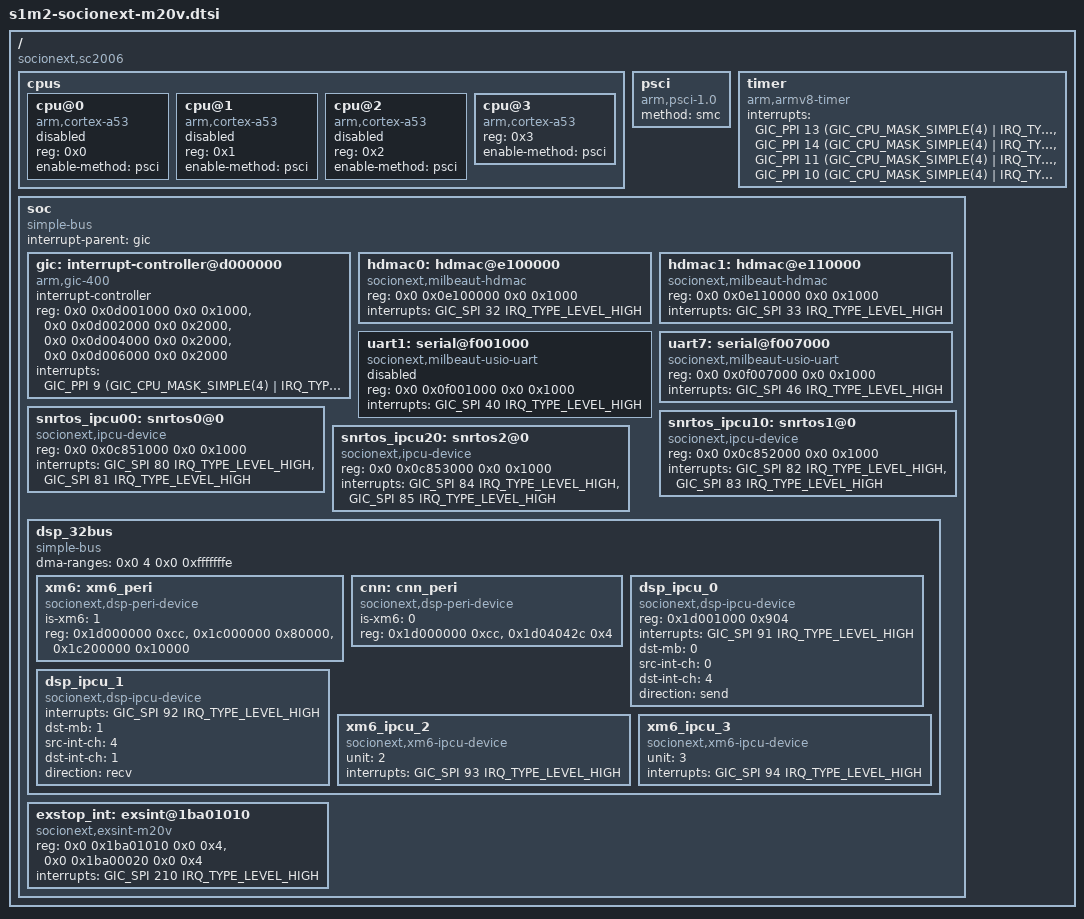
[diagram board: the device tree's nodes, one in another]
// SPDX-License-Identifier: GPL-2.0
/*
 * Reconstructed Device Tree Source for Socionext Milbeaut M20V (Karine / SC2006A)
 * Target: Panasonic LUMIX S1M2 (DC-S1M2)
 *
 * Platform: ARM64 Quad-Core Cortex-A53
 * AMP Architecture: Cores 0-2 (TOPPERS/ITRON RTOS), Core 3 (Linux 4.19)
 */

#include <dt-bindings/interrupt-controller/arm-gic.h>

/ {
	compatible = "socionext,sc2006", "socionext,m20v";
	#address-cells = <2>;
	#size-cells = <2>;

	cpus {
		#address-cells = <1>;
		#size-cells = <0>;

		cpu@0 {
			device_type = "cpu";
			compatible = "arm,cortex-a53", "arm,armv8";
			reg = <0x0>;
			enable-method = "psci";
			status = "disabled"; /* Reserved for RTOS Core 0: Shutter / ISP / Sensor / AF */
		};

		cpu@1 {
			device_type = "cpu";
			compatible = "arm,cortex-a53", "arm,armv8";
			reg = <0x1>;
			enable-method = "psci";
			status = "disabled"; /* Reserved for RTOS Core 1: DSP / CNN / Video Engine */
		};

		cpu@2 {
			device_type = "cpu";
			compatible = "arm,cortex-a53", "arm,armv8";
			reg = <0x2>;
			enable-method = "psci";
			status = "disabled"; /* Reserved for RTOS Core 2: Storage SD / Filesystem */
		};

		cpu@3 {
			device_type = "cpu";
			compatible = "arm,cortex-a53", "arm,armv8";
			reg = <0x3>;
			enable-method = "psci";
			status = "okay";     /* Linux 4.19 System Host: Wi-Fi, USB, OSD, Network */
		};
	};

	psci {
		compatible = "arm,psci-1.0", "arm,psci-0.2";
		method = "smc";
	};

	timer {
		compatible = "arm,armv8-timer";
		interrupts = <GIC_PPI 13 (GIC_CPU_MASK_SIMPLE(4) | IRQ_TYPE_LEVEL_LOW)>,
			     <GIC_PPI 14 (GIC_CPU_MASK_SIMPLE(4) | IRQ_TYPE_LEVEL_LOW)>,
			     <GIC_PPI 11 (GIC_CPU_MASK_SIMPLE(4) | IRQ_TYPE_LEVEL_LOW)>,
			     <GIC_PPI 10 (GIC_CPU_MASK_SIMPLE(4) | IRQ_TYPE_LEVEL_LOW)>;
	};

	soc {
		compatible = "simple-bus";
		#address-cells = <2>;
		#size-cells = <2>;
		ranges;
		interrupt-parent = <&gic>;

		gic: interrupt-controller@d000000 {
			compatible = "arm,gic-400";
			#interrupt-cells = <3>;
			interrupt-controller;
			reg = <0x0 0x0d001000 0x0 0x1000>,
			      <0x0 0x0d002000 0x0 0x2000>,
			      <0x0 0x0d004000 0x0 0x2000>,
			      <0x0 0x0d006000 0x0 0x2000>;
			interrupts = <GIC_PPI 9 (GIC_CPU_MASK_SIMPLE(4) | IRQ_TYPE_LEVEL_HIGH)>;
		};

		/* Hardware DMA Controllers */
		hdmac0: hdmac@e100000 {
			compatible = "socionext,milbeaut-hdmac";
			reg = <0x0 0x0e100000 0x0 0x1000>;
			interrupts = <GIC_SPI 32 IRQ_TYPE_LEVEL_HIGH>;
			#dma-cells = <1>;
		};

		hdmac1: hdmac@e110000 {
			compatible = "socionext,milbeaut-hdmac";
			reg = <0x0 0x0e110000 0x0 0x1000>;
			interrupts = <GIC_SPI 33 IRQ_TYPE_LEVEL_HIGH>;
			#dma-cells = <1>;
		};

		/* UART Controllers */
		uart1: serial@f001000 {
			compatible = "socionext,milbeaut-usio-uart";
			reg = <0x0 0x0f001000 0x0 0x1000>;
			interrupts = <GIC_SPI 40 IRQ_TYPE_LEVEL_HIGH>;
			status = "disabled";
		};

		uart7: serial@f007000 {
			compatible = "socionext,milbeaut-usio-uart";
			reg = <0x0 0x0f007000 0x0 0x1000>;
			interrupts = <GIC_SPI 46 IRQ_TYPE_LEVEL_HIGH>;
			status = "okay";
		};

		/* Inter-Processor Communication Unit (IPCU) Controllers */
		snrtos_ipcu00: snrtos0@0 {
			compatible = "socionext,ipcu-device";
			reg = <0x0 0x0c851000 0x0 0x1000>;
			interrupts = <GIC_SPI 80 IRQ_TYPE_LEVEL_HIGH>,
				     <GIC_SPI 81 IRQ_TYPE_LEVEL_HIGH>;
			status = "okay";
		};

		snrtos_ipcu10: snrtos1@0 {
			compatible = "socionext,ipcu-device";
			reg = <0x0 0x0c852000 0x0 0x1000>;
			interrupts = <GIC_SPI 82 IRQ_TYPE_LEVEL_HIGH>,
				     <GIC_SPI 83 IRQ_TYPE_LEVEL_HIGH>;
			status = "okay";
		};

		snrtos_ipcu20: snrtos2@0 {
			compatible = "socionext,ipcu-device";
			reg = <0x0 0x0c853000 0x0 0x1000>;
			interrupts = <GIC_SPI 84 IRQ_TYPE_LEVEL_HIGH>,
				     <GIC_SPI 85 IRQ_TYPE_LEVEL_HIGH>;
			status = "okay";
		};

		/* Dedicated 32-bit Peripheral Bus for XM6 DSP & CNN */
		dsp_32bus {
			compatible = "simple-bus";
			#address-cells = <1>;
			#size-cells = <1>;
			ranges = <0x0 0x0 0x0 0xfffffffe>;
			dma-ranges = <0x0 4 0x0 0xfffffffe>;

			/* CEVA XM6 Dual-Core Vector DSP */
			xm6: xm6_peri {
				compatible = "socionext,dsp-peri-device";
				is-xm6 = <1>;
				reg = <0x1d000000 0xcc>,       /* Control registers */
				      <0x1c000000 0x80000>,    /* 512 KiB DTCM */
				      <0x1c200000 0x10000>;    /* 64 KiB ITCM */
				status = "okay";
			};

			/* CNN Deep Learning Accelerator */
			cnn: cnn_peri {
				compatible = "socionext,dsp-peri-device";
				is-xm6 = <0>;
				reg = <0x1d000000 0xcc>,
				      <0x1d04042c 0x4>;
				status = "okay";
			};

			/* DSP IPCU Mailboxes */
			dsp_ipcu_0: dsp_ipcu_0 {
				compatible = "socionext,dsp-ipcu-device";
				reg = <0x1d001000 0x904>;
				interrupts = <GIC_SPI 91 IRQ_TYPE_LEVEL_HIGH>;
				dst-mb = <0>;
				src-int-ch = <0>;
				dst-int-ch = <4>;
				direction = "send";
			};

			dsp_ipcu_1: dsp_ipcu_1 {
				compatible = "socionext,dsp-ipcu-device";
				interrupts = <GIC_SPI 92 IRQ_TYPE_LEVEL_HIGH>;
				dst-mb = <1>;
				src-int-ch = <4>;
				dst-int-ch = <1>;
				direction = "recv";
			};

			xm6_ipcu_2: xm6_ipcu_2 {
				compatible = "socionext,xm6-ipcu-device";
				unit = <2>;
				interrupts = <GIC_SPI 93 IRQ_TYPE_LEVEL_HIGH>;
			};

			xm6_ipcu_3: xm6_ipcu_3 {
				compatible = "socionext,xm6-ipcu-device";
				unit = <3>;
				interrupts = <GIC_SPI 94 IRQ_TYPE_LEVEL_HIGH>;
			};
		};

		/* External Interrupt Controller (EXSINT/EXIU) */
		exstop_int: exsint@1ba01010 {
			compatible = "socionext,exsint-m20v";
			#address-cells = <1>;
			#size-cells = <1>;
			reg = <0x0 0x1ba01010 0x0 0x4>,
			      <0x0 0x1ba00020 0x0 0x4>;
			reg-names = "intstat", "intmsk";
			interrupts = <GIC_SPI 210 IRQ_TYPE_LEVEL_HIGH>;
		};
	};
};
